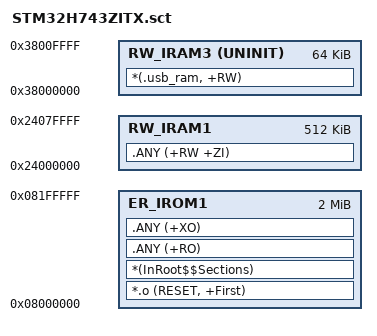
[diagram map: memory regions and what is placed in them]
;********************************************************************************
;* Scatter file for STM32H743ZIT6  (generated to mirror STM32H743ZITX_FLASH.ld)
;*
;*   FLASH   : 0x08000000  2048 KB  (code + RO)
;*   RAM_D1  : 0x24000000   512 KB  (.data / .bss / heap / stack)
;*   RAM_D3  : 0x38000000    64 KB  (usb_ram, UNINIT -> USB OTG DMA buffers,
;*                                    mapped NON-CACHEABLE by MPU Region 2)
;*
;*   DTCM (0x20000000) and RAM_D2 (0x30000000) are DELIBERATELY absent: they are
;*   carved at runtime by bsp/sram_pool.c and must not be reserved by the linker.
;********************************************************************************
LR_IROM1 0x08000000 0x00200000 {
  ER_IROM1 0x08000000 0x00200000 {
    *.o (RESET, +First)
    *(InRoot$$Sections)
    .ANY (+RO)
    .ANY (+XO)
  }

  RW_IRAM1 0x24000000 0x00080000 {
    .ANY (+RW +ZI)
  }

  ; USB / TinyUSB DMA buffers (OTG internal DMA writes here directly).
  ; UNINIT so the startup code does not zero / touch them.
  RW_IRAM3 0x38000000 UNINIT 0x00010000 {
    *(.usb_ram, +RW)
  }
}
